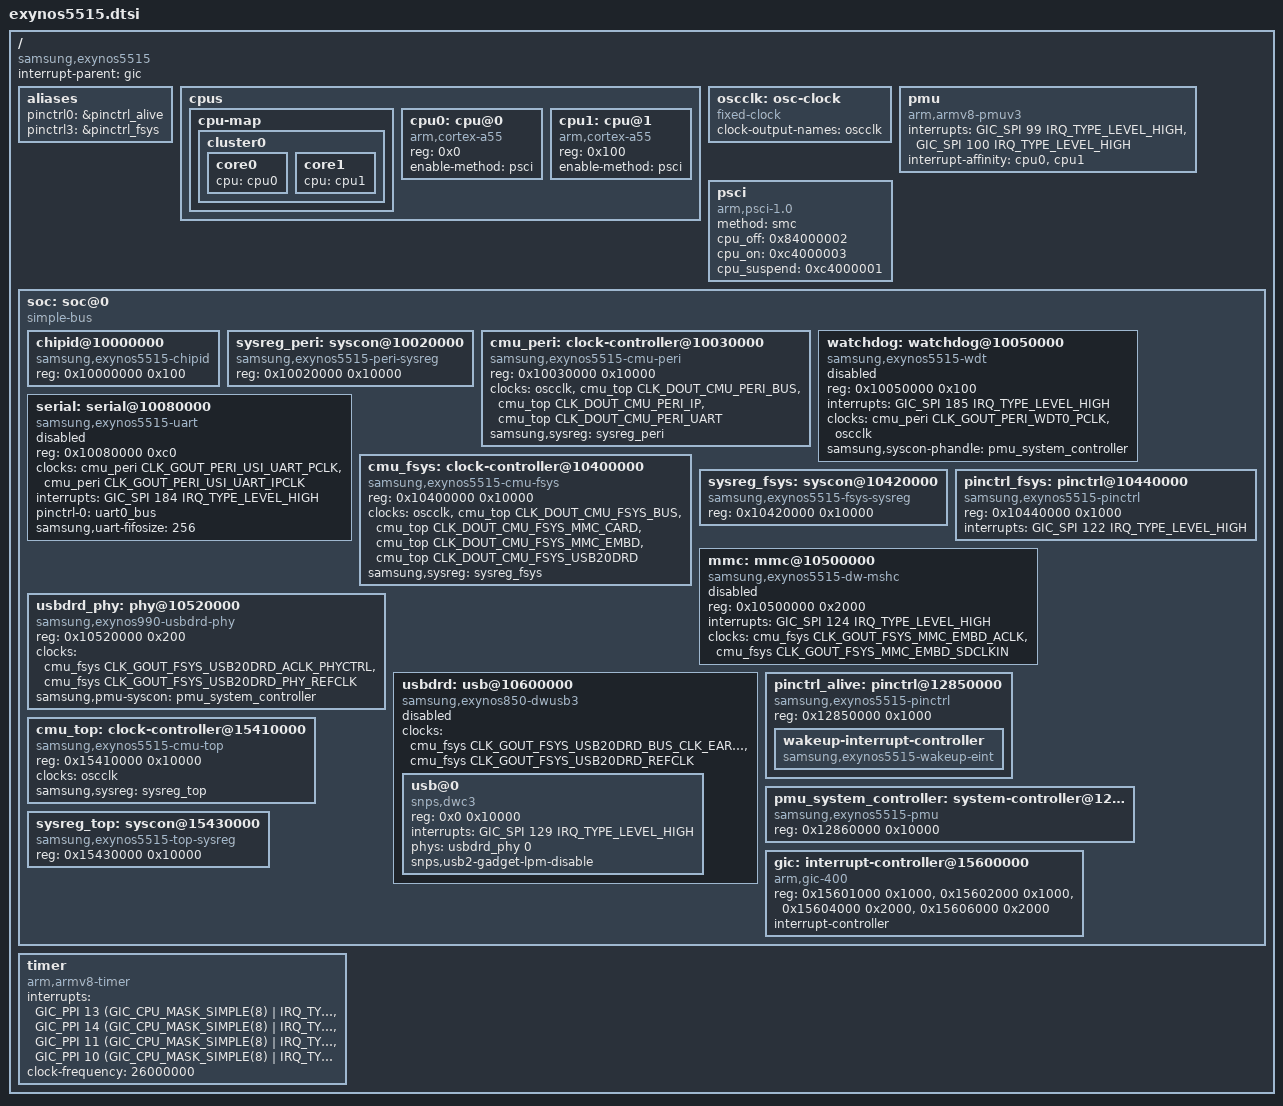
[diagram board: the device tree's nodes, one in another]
// SPDX-License-Identifier: GPL-2.0-or-later
/*
 * Samsung Exynos 5515 SoC device tree source
 *
 * Copyright (c) 2026 Aiden Isik <aidenisik+git@member.fsf.org>
 */

#include <dt-bindings/clock/samsung,exynos5515-cmu.h>
#include <dt-bindings/interrupt-controller/arm-gic.h>

/ {
	compatible = "samsung,exynos5515";
	#address-cells = <2>;
	#size-cells = <1>;

	interrupt-parent = <&gic>;

	aliases {
		pinctrl0 = &pinctrl_alive;
		pinctrl3 = &pinctrl_fsys;
	};

	cpus {
		#address-cells = <1>;
		#size-cells = <0>;

		cpu-map {
			cluster0 {
				core0 {
					cpu = <&cpu0>;
				};

				core1 {
					cpu = <&cpu1>;
				};
			};
		};

		cpu0: cpu@0 {
			device_type = "cpu";
			compatible = "arm,cortex-a55";
			reg = <0x0>;
			enable-method = "psci";
		};

		cpu1: cpu@1 {
			device_type = "cpu";
			compatible = "arm,cortex-a55";
			reg = <0x100>;
			enable-method = "psci";
		};
	};

	oscclk: osc-clock {
		compatible = "fixed-clock";
		#clock-cells = <0>;
		clock-output-names = "oscclk";
	};

	pmu {
		compatible = "arm,armv8-pmuv3";
		interrupts = <GIC_SPI 99 IRQ_TYPE_LEVEL_HIGH>,
			     <GIC_SPI 100 IRQ_TYPE_LEVEL_HIGH>;
		interrupt-affinity = <&cpu0>,
				     <&cpu1>;
	};

	psci {
		compatible = "arm,psci-1.0";
		method = "smc";
		cpu_off = <0x84000002>;
		cpu_on = <0xc4000003>;
		cpu_suspend = <0xc4000001>;
	};

	soc: soc@0 {
		compatible = "simple-bus";
		ranges = <0x0 0x0 0x0 0x20000000>;

		#address-cells = <1>;
		#size-cells = <1>;

		chipid@10000000 {
			compatible = "samsung,exynos5515-chipid",
				     "samsung,exynos850-chipid";
			reg = <0x10000000 0x100>;
		};

		sysreg_peri: syscon@10020000 {
			compatible = "samsung,exynos5515-peri-sysreg", "syscon";
			reg = <0x10020000 0x10000>;
		};

		cmu_peri: clock-controller@10030000 {
			compatible = "samsung,exynos5515-cmu-peri";
			reg = <0x10030000 0x10000>;
			#clock-cells = <1>;

			clocks = <&oscclk>,
				 <&cmu_top CLK_DOUT_CMU_PERI_BUS>,
				 <&cmu_top CLK_DOUT_CMU_PERI_IP>,
				 <&cmu_top CLK_DOUT_CMU_PERI_UART>;
			clock-names = "oscclk",
				      "bus",
				      "ip",
				      "uart";
			samsung,sysreg = <&sysreg_peri>;
		};

		watchdog: watchdog@10050000 {
			compatible = "samsung,exynos5515-wdt";
			reg = <0x10050000 0x100>;
			interrupts = <GIC_SPI 185 IRQ_TYPE_LEVEL_HIGH>;
			clocks = <&cmu_peri CLK_GOUT_PERI_WDT0_PCLK>,
				 <&oscclk>;
			clock-names = "watchdog",
				      "watchdog_src";
			samsung,syscon-phandle = <&pmu_system_controller>;
			status = "disabled";
		};

		/* TODO: This should be within a USI block */
		serial: serial@10080000 {
			compatible = "samsung,exynos5515-uart",
				     "google,gs101-uart";
			reg = <0x10080000 0xc0>;
			ranges;
			#address-cells = <1>;
			#size-cells = <1>;
			clocks = <&cmu_peri CLK_GOUT_PERI_USI_UART_PCLK>,
				 <&cmu_peri CLK_GOUT_PERI_USI_UART_IPCLK>;
			clock-names = "uart", "clk_uart_baud0";
			interrupts = <GIC_SPI 184 IRQ_TYPE_LEVEL_HIGH>;
			pinctrl-0 = <&uart0_bus>;
			pinctrl-names = "default";
			samsung,uart-fifosize = <256>;
			status = "disabled";
		};

		cmu_fsys: clock-controller@10400000 {
			compatible = "samsung,exynos5515-cmu-fsys";
			reg = <0x10400000 0x10000>;
			#clock-cells = <1>;

			clocks = <&oscclk>,
				 <&cmu_top CLK_DOUT_CMU_FSYS_BUS>,
				 <&cmu_top CLK_DOUT_CMU_FSYS_MMC_CARD>,
				 <&cmu_top CLK_DOUT_CMU_FSYS_MMC_EMBD>,
				 <&cmu_top CLK_DOUT_CMU_FSYS_USB20DRD>;
			clock-names = "oscclk",
				      "bus",
				      "mmc_card",
				      "mmc_embd",
				      "usb20drd";
			samsung,sysreg = <&sysreg_fsys>;
		};

		sysreg_fsys: syscon@10420000 {
			compatible = "samsung,exynos5515-fsys-sysreg", "syscon";
			reg = <0x10420000 0x10000>;
		};

		pinctrl_fsys: pinctrl@10440000 {
			compatible = "samsung,exynos5515-pinctrl";
			reg = <0x10440000 0x1000>;
			interrupts = <GIC_SPI 122 IRQ_TYPE_LEVEL_HIGH>;
		};

		mmc: mmc@10500000 {
			compatible = "samsung,exynos5515-dw-mshc",
				     "samsung,exynos7-dw-mshc";
			reg = <0x10500000 0x2000>;
			interrupts = <GIC_SPI 124 IRQ_TYPE_LEVEL_HIGH>;

			clocks = <&cmu_fsys CLK_GOUT_FSYS_MMC_EMBD_ACLK>,
				 <&cmu_fsys CLK_GOUT_FSYS_MMC_EMBD_SDCLKIN>;
			clock-names = "biu", "ciu";
			status = "disabled";
		};

		usbdrd_phy: phy@10520000 {
			compatible = "samsung,exynos990-usbdrd-phy";
			reg = <0x10520000 0x200>;
			#phy-cells = <1>;

			clocks = <&cmu_fsys CLK_GOUT_FSYS_USB20DRD_ACLK_PHYCTRL>,
				 <&cmu_fsys CLK_GOUT_FSYS_USB20DRD_PHY_REFCLK>;
			clock-names = "phy", "ref";

			samsung,pmu-syscon = <&pmu_system_controller>;
		};

		usbdrd: usb@10600000 {
			compatible = "samsung,exynos850-dwusb3";
			ranges = <0x0 0x10600000 0x10000>;
			#address-cells = <1>;
			#size-cells = <1>;

			clocks = <&cmu_fsys CLK_GOUT_FSYS_USB20DRD_BUS_CLK_EARLY>,
				 <&cmu_fsys CLK_GOUT_FSYS_USB20DRD_REFCLK>;
			clock-names = "bus_early", "ref";
			status = "disabled";

			usb@0 {
				compatible = "snps,dwc3";
				reg = <0x0 0x10000>;
				interrupts = <GIC_SPI 129 IRQ_TYPE_LEVEL_HIGH>;

				phy-names = "usb2-phy";
				phys = <&usbdrd_phy 0>;

				snps,usb2-gadget-lpm-disable;
			};
		};

		pinctrl_alive: pinctrl@12850000 {
			compatible = "samsung,exynos5515-pinctrl";
			reg = <0x12850000 0x1000>;

			wakeup-interrupt-controller {
				compatible = "samsung,exynos5515-wakeup-eint",
					     "samsung,exynos7-wakeup-eint";
			};
		};

		pmu_system_controller: system-controller@12860000 {
			compatible = "samsung,exynos5515-pmu", "samsung,exynos7-pmu", "syscon";
			reg = <0x12860000 0x10000>;
		};

		cmu_top: clock-controller@15410000 {
			compatible = "samsung,exynos5515-cmu-top";
			reg = <0x15410000 0x10000>;
			#clock-cells = <1>;

			clocks = <&oscclk>;
			clock-names = "oscclk";
			samsung,sysreg = <&sysreg_top>;
		};

		sysreg_top: syscon@15430000 {
			compatible = "samsung,exynos5515-top-sysreg", "syscon";
			reg = <0x15430000 0x10000>;
		};

		gic: interrupt-controller@15600000 {
			compatible = "arm,gic-400";
			reg = <0x15601000 0x1000>,
			      <0x15602000 0x1000>,
			      <0x15604000 0x2000>,
			      <0x15606000 0x2000>;
			#interrupt-cells = <3>;
			interrupt-controller;
			#address-cells = <0>;
		};
	};

	timer {
		compatible = "arm,armv8-timer";
		/*
		 * Hypervisor Virtual Timer interrupt is not wired to GIC
		 * TODO: This was an assumption based off of other Exynos DTs, but is probably wrong.
		 * Test whether GIC_PPI 12 (GIC_CPU_MASK_SIMPLE(8) | IRQ_TYPE_LEVEL_LOW) works when not working on other things.
		 */
		interrupts = <GIC_PPI 13 (GIC_CPU_MASK_SIMPLE(8) | IRQ_TYPE_LEVEL_LOW)>,
			     <GIC_PPI 14 (GIC_CPU_MASK_SIMPLE(8) | IRQ_TYPE_LEVEL_LOW)>,
			     <GIC_PPI 11 (GIC_CPU_MASK_SIMPLE(8) | IRQ_TYPE_LEVEL_LOW)>,
			     <GIC_PPI 10 (GIC_CPU_MASK_SIMPLE(8) | IRQ_TYPE_LEVEL_LOW)>;
		/*
		 * Non-updatable, broken stock Samsung bootloader does not
		 * configure CNTFRQ_EL0
		 */
		clock-frequency = <26000000>;
	};
};

#include "exynos5515-pinctrl.dtsi"
#include "arm/samsung/exynos-syscon-restart.dtsi"
